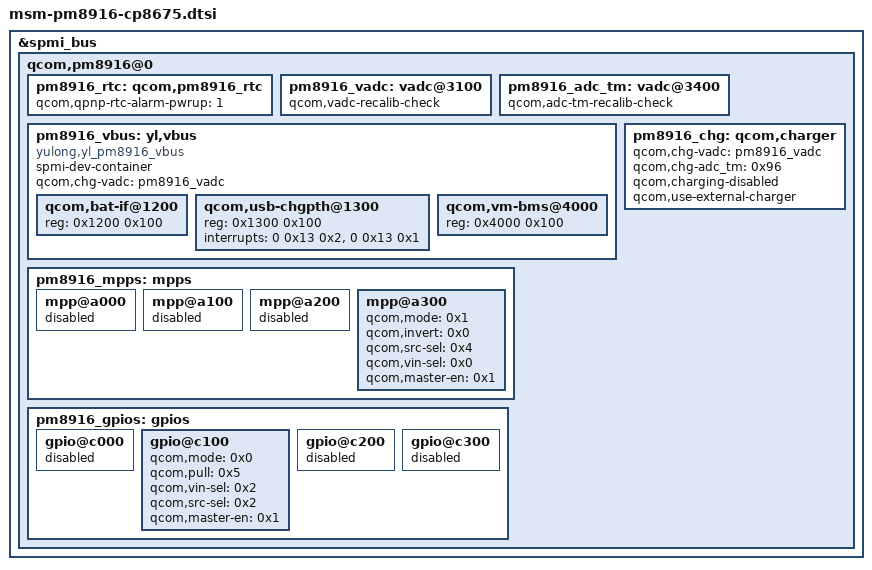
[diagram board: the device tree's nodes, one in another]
/* Copyright (c) 2013-2014, The Linux Foundation. All rights reserved.
 *
 * This program is free software; you can redistribute it and/or modify
 * it under the terms of the GNU General Public License version 2 and
 * only version 2 as published by the Free Software Foundation.
 *
 * This program is distributed in the hope that it will be useful,
 * but WITHOUT ANY WARRANTY; without even the implied warranty of
 * MERCHANTABILITY or FITNESS FOR A PARTICULAR PURPOSE.  See the
 * GNU General Public License for more details.
 */

&spmi_bus {
	qcom,pm8916@0 {
		pm8916_rtc: qcom,pm8916_rtc {
			qcom,qpnp-rtc-alarm-pwrup = <1>;
		};

		pm8916_vadc: vadc@3100 {
			qcom,vadc-recalib-check;
		};

		pm8916_adc_tm: vadc@3400 {
			qcom,adc-tm-recalib-check;
		};

		pm8916_vbus: yl,vbus {
			spmi-dev-container;
			compatible = "yulong,yl_pm8916_vbus";
			#address-cells = <1>;
			#size-cells = <1>;
			status = "ok";
			qcom,chg-vadc = <&pm8916_vadc>;
			qcom,bat-if@1200 {
				reg = <0x1200 0x100>;
			};
			qcom,usb-chgpth@1300 {
				reg = <0x1300 0x100>;
				interrupts = <0 0x13 0x2>,
					<0 0x13 0x1>;
				interrupt-names = "chg-gone",
					"usbin-valid";
			};
			qcom,vm-bms@4000 {
				reg = <0x4000 0x100>;
			};
		};

		pm8916_mpps: mpps {
			mpp@a000 {
				status = "disabled";
			};

			mpp@a100 {
				status = "disabled";
			};

			mpp@a200 {
				status = "disabled";
			};

			mpp@a300 {
				qcom,mode = <0x1>;
				qcom,invert = <0x0>;
				qcom,src-sel = <0x4>;
				qcom,vin-sel = <0x0>;
				qcom,master-en = <0x1>;
			};
		};

		pm8916_gpios: gpios {
			linux,phandle = <0xa6>;
			phandle = <0xa6>;

			gpio@c000 {
				status = "disabled";
			};

			gpio@c100 {
				qcom,mode = <0x0>;
				qcom,pull = <0x5>;
				qcom,vin-sel = <0x2>;
				qcom,src-sel = <0x2>;
				qcom,master-en = <0x1>;
			};

			gpio@c200 {
				status = "disabled";
			};

			gpio@c300 {
				status = "disabled";
			};
		};

		pm8916_chg: qcom,charger {
			qcom,chg-vadc = <&pm8916_vadc>;
			qcom,chg-adc_tm = <0x96>;
			qcom,charging-disabled;
			qcom,use-external-charger;
		};

	};
};
